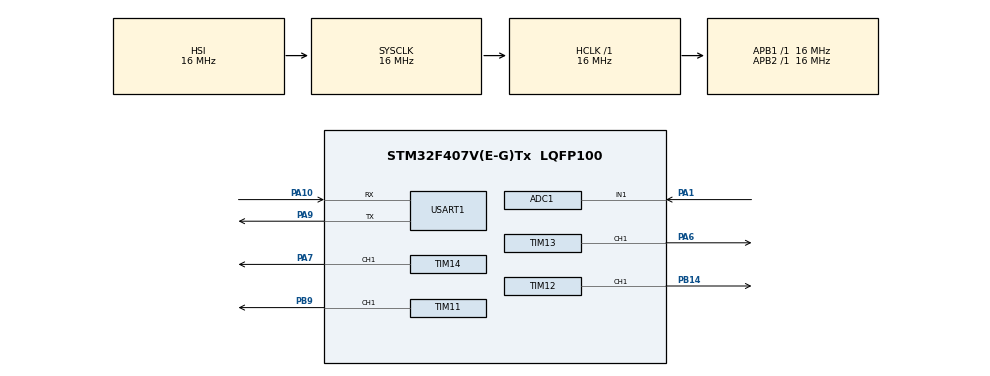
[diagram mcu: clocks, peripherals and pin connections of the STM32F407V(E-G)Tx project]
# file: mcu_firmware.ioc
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ADC1.Channel-1\#ChannelRegularConversion=ADC_CHANNEL_1
ADC1.ContinuousConvMode=ENABLE
ADC1.EOCSelection=ADC_EOC_SEQ_CONV
ADC1.NbrOfConversion=1
ADC1.NbrOfConversionFlag=1
ADC1.Rank-1\#ChannelRegularConversion=1
ADC1.SamplingTime-1\#ChannelRegularConversion=ADC_SAMPLETIME_3CYCLES
ADC1.master=1
Mcu.Family=STM32F4
Mcu.Name=STM32F407V(E-G)Tx
Mcu.Package=LQFP100
NVIC.PriorityGroup=NVIC_PRIORITYGROUP_4
NVIC.TIM1_TRG_COM_TIM11_IRQn=true\:0\:0\:false\:false\:true\:true\:true\:true
NVIC.TIM8_BRK_TIM12_IRQn=true\:0\:0\:false\:false\:true\:true\:true\:true
NVIC.TIM8_TRG_COM_TIM14_IRQn=true\:0\:0\:false\:false\:true\:true\:true\:true
NVIC.TIM8_UP_TIM13_IRQn=true\:0\:0\:false\:false\:true\:true\:true\:true
NVIC.USART1_IRQn=true\:0\:0\:false\:false\:true\:true\:true\:true
PA1.Signal=ADCx_IN1
PA10.Mode=Asynchronous
PA10.Signal=USART1_RX
PA6.GPIO_PuPd=GPIO_PULLDOWN
PA6.GPIO_Speed=GPIO_SPEED_FREQ_VERY_HIGH
PA6.Signal=S_TIM13_CH1
PA7.GPIO_PuPd=GPIO_PULLDOWN
PA7.GPIO_Speed=GPIO_SPEED_FREQ_VERY_HIGH
PA7.Signal=S_TIM14_CH1
PA9.Mode=Asynchronous
PA9.Signal=USART1_TX
PB14.GPIO_PuPd=GPIO_PULLDOWN
PB14.GPIO_Speed=GPIO_SPEED_FREQ_VERY_HIGH
PB14.Signal=S_TIM12_CH1
PB9.GPIO_PuPd=GPIO_PULLDOWN
PB9.GPIO_Speed=GPIO_SPEED_FREQ_VERY_HIGH
PB9.Signal=S_TIM11_CH1
PH0-OSC_IN.Mode=HSE-External-Oscillator
PH0-OSC_IN.Signal=RCC_OSC_IN
PH1-OSC_OUT.Mode=HSE-External-Oscillator
PH1-OSC_OUT.Signal=RCC_OSC_OUT
ProjectManager.HeapSize=0x200
ProjectManager.StackSize=0x400
ProjectManager.TargetToolchain=MDK-ARM V5.32
RCC.AHBFreq_Value=16000000
RCC.APB1Freq_Value=16000000
RCC.APB1TimFreq_Value=16000000
RCC.APB2Freq_Value=16000000
RCC.APB2TimFreq_Value=16000000
RCC.CortexFreq_Value=16000000
RCC.HCLKFreq_Value=16000000
RCC.HSE_VALUE=25000000
RCC.HSI_VALUE=16000000
RCC.LSE_VALUE=32768
RCC.SYSCLKFreq_VALUE=16000000
RCC.VCOOutputFreq_Value=192000000
SH.ADCx_IN1.0=ADC1_IN1,IN1
SH.S_TIM11_CH1.0=TIM11_CH1,PWM Generation1 CH1
SH.S_TIM12_CH1.0=TIM12_CH1,PWM Generation1 CH1
SH.S_TIM13_CH1.0=TIM13_CH1,PWM Generation1 CH1
SH.S_TIM14_CH1.0=TIM14_CH1,PWM Generation1 CH1
TIM11.Channel=TIM_CHANNEL_1
TIM11.Prescaler=15
TIM12.Channel-PWM\ Generation1\ CH1=TIM_CHANNEL_1
TIM12.Prescaler=15
TIM13.Channel=TIM_CHANNEL_1
TIM13.Prescaler=15
TIM14.Channel=TIM_CHANNEL_1
TIM14.Prescaler=15
USART1.VirtualMode=VM_ASYNC
VP_TIM11_VS_ClockSourceINT.Mode=Enable_Timer
VP_TIM12_VS_ClockSourceINT.Mode=Internal
VP_TIM13_VS_ClockSourceINT.Mode=Enable_Timer
VP_TIM14_VS_ClockSourceINT.Mode=Enable_Timer
board=custom

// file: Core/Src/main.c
/* USER CODE BEGIN Header */
/**
  ******************************************************************************
  * @file           : main.c
  * @brief          : Main program body
  ******************************************************************************
  * @attention
  *
  * Copyright (c) 2025 STMicroelectronics.
  * All rights reserved.
  *
  * This software is licensed under terms that can be found in the LICENSE file
  * in the root directory of this software component.
  * If no LICENSE file comes with this software, it is provided AS-IS.
  *
  ******************************************************************************
  */
/* USER CODE END Header */
#include "main.h"

/* USER CODE BEGIN Includes */
#include "func.h"
/* USER CODE END Includes */

ADC_HandleTypeDef hadc1;

TIM_HandleTypeDef htim11;
TIM_HandleTypeDef htim12;
TIM_HandleTypeDef htim13;
TIM_HandleTypeDef htim14;

UART_HandleTypeDef huart1;

void SystemClock_Config(void);
static void MX_GPIO_Init(void);
static void MX_TIM11_Init(void);
static void MX_TIM12_Init(void);
static void MX_TIM13_Init(void);
static void MX_TIM14_Init(void);
static void MX_USART1_UART_Init(void);
static void MX_ADC1_Init(void);

/* USER CODE BEGIN 0 */
uint16_t value;
/* USER CODE END 0 */

int main(void)
{

  /* MCU Configuration--------------------------------------------------------*/

  /* Reset of all peripherals, Initializes the Flash interface and the Systick. */
  HAL_Init();

  /* Configure the system clock */
  SystemClock_Config();

  /* Initialize all configured peripherals */
  MX_GPIO_Init();
  MX_TIM11_Init();
  MX_TIM12_Init();
  MX_TIM13_Init();
  MX_TIM14_Init();
  MX_USART1_UART_Init();
  MX_ADC1_Init();
  /* USER CODE BEGIN 2 */

	StartAxis(&htim11);

  /* USER CODE END 2 */

  /* Infinite loop */
  while (1)
  {
		HAL_ADC_Start(&hadc1);
		HAL_ADC_PollForConversion(&hadc1, 10);
		value = HAL_ADC_GetValue(&hadc1);
		HAL_ADC_Stop(&hadc1);
		if (value < 850)
		{
			value = 850;
		}
		SetPeriod(X_axis_htim, value/16);
		HAL_Delay(100);
  }
}

void SystemClock_Config(void)
{
  RCC_OscInitTypeDef RCC_OscInitStruct = {0};
  RCC_ClkInitTypeDef RCC_ClkInitStruct = {0};

  /** Configure the main internal regulator output voltage
  */
  __HAL_RCC_PWR_CLK_ENABLE();
  __HAL_PWR_VOLTAGESCALING_CONFIG(PWR_REGULATOR_VOLTAGE_SCALE1);

  /** Initializes the RCC Oscillators according to the specified parameters
  * in the RCC_OscInitTypeDef structure.
  */
  RCC_OscInitStruct.OscillatorType = RCC_OSCILLATORTYPE_HSI;
  RCC_OscInitStruct.HSIState = RCC_HSI_ON;
  RCC_OscInitStruct.HSICalibrationValue = RCC_HSICALIBRATION_DEFAULT;
  RCC_OscInitStruct.PLL.PLLState = RCC_PLL_NONE;
  if (HAL_RCC_OscConfig(&RCC_OscInitStruct) != HAL_OK)
  {
    Error_Handler();
  }

  /** Initializes the CPU, AHB and APB buses clocks
  */
  RCC_ClkInitStruct.ClockType = RCC_CLOCKTYPE_HCLK|RCC_CLOCKTYPE_SYSCLK
                              |RCC_CLOCKTYPE_PCLK1|RCC_CLOCKTYPE_PCLK2;
  RCC_ClkInitStruct.SYSCLKSource = RCC_SYSCLKSOURCE_HSI;
  RCC_ClkInitStruct.AHBCLKDivider = RCC_SYSCLK_DIV1;
  RCC_ClkInitStruct.APB1CLKDivider = RCC_HCLK_DIV1;
  RCC_ClkInitStruct.APB2CLKDivider = RCC_HCLK_DIV1;

  if (HAL_RCC_ClockConfig(&RCC_ClkInitStruct, FLASH_LATENCY_0) != HAL_OK)
  {
    Error_Handler();
  }
}

static void MX_ADC1_Init(void)
{

  ADC_ChannelConfTypeDef sConfig = {0};

  /** Configure the global features of the ADC (Clock, Resolution, Data Alignment and number of conversion)
  */
  hadc1.Instance = ADC1;
  hadc1.Init.ClockPrescaler = ADC_CLOCK_SYNC_PCLK_DIV2;
  hadc1.Init.Resolution = ADC_RESOLUTION_12B;
  hadc1.Init.ScanConvMode = DISABLE;
  hadc1.Init.ContinuousConvMode = ENABLE;
  hadc1.Init.DiscontinuousConvMode = DISABLE;
  hadc1.Init.ExternalTrigConvEdge = ADC_EXTERNALTRIGCONVEDGE_NONE;
  hadc1.Init.ExternalTrigConv = ADC_SOFTWARE_START;
  hadc1.Init.DataAlign = ADC_DATAALIGN_RIGHT;
  hadc1.Init.NbrOfConversion = 1;
  hadc1.Init.DMAContinuousRequests = DISABLE;
  hadc1.Init.EOCSelection = ADC_EOC_SEQ_CONV;
  if (HAL_ADC_Init(&hadc1) != HAL_OK)
  {
    Error_Handler();
  }

  /** Configure for the selected ADC regular channel its corresponding rank in the sequencer and its sample time.
  */
  sConfig.Channel = ADC_CHANNEL_1;
  sConfig.Rank = 1;
  sConfig.SamplingTime = ADC_SAMPLETIME_3CYCLES;
  if (HAL_ADC_ConfigChannel(&hadc1, &sConfig) != HAL_OK)
  {
    Error_Handler();
  }

}

static void MX_TIM11_Init(void)
{

  TIM_OC_InitTypeDef sConfigOC = {0};

  htim11.Instance = TIM11;
  htim11.Init.Prescaler = 15;
  htim11.Init.CounterMode = TIM_COUNTERMODE_UP;
  htim11.Init.Period = 65535;
  htim11.Init.ClockDivision = TIM_CLOCKDIVISION_DIV1;
  htim11.Init.AutoReloadPreload = TIM_AUTORELOAD_PRELOAD_DISABLE;
  if (HAL_TIM_Base_Init(&htim11) != HAL_OK)
  {
    Error_Handler();
  }
  if (HAL_TIM_PWM_Init(&htim11) != HAL_OK)
  {
    Error_Handler();
  }
  sConfigOC.OCMode = TIM_OCMODE_PWM1;
  sConfigOC.Pulse = 0;
  sConfigOC.OCPolarity = TIM_OCPOLARITY_HIGH;
  sConfigOC.OCFastMode = TIM_OCFAST_DISABLE;
  if (HAL_TIM_PWM_ConfigChannel(&htim11, &sConfigOC, TIM_CHANNEL_1) != HAL_OK)
  {
    Error_Handler();
  }
  HAL_TIM_MspPostInit(&htim11);

}

static void MX_TIM12_Init(void)
{

  TIM_ClockConfigTypeDef sClockSourceConfig = {0};
  TIM_OC_InitTypeDef sConfigOC = {0};

  htim12.Instance = TIM12;
  htim12.Init.Prescaler = 15;
  htim12.Init.CounterMode = TIM_COUNTERMODE_UP;
  htim12.Init.Period = 65535;
  htim12.Init.ClockDivision = TIM_CLOCKDIVISION_DIV1;
  htim12.Init.AutoReloadPreload = TIM_AUTORELOAD_PRELOAD_DISABLE;
  if (HAL_TIM_Base_Init(&htim12) != HAL_OK)
  {
    Error_Handler();
  }
  sClockSourceConfig.ClockSource = TIM_CLOCKSOURCE_INTERNAL;
  if (HAL_TIM_ConfigClockSource(&htim12, &sClockSourceConfig) != HAL_OK)
  {
    Error_Handler();
  }
  if (HAL_TIM_PWM_Init(&htim12) != HAL_OK)
  {
    Error_Handler();
  }
  sConfigOC.OCMode = TIM_OCMODE_PWM1;
  sConfigOC.Pulse = 0;
  sConfigOC.OCPolarity = TIM_OCPOLARITY_HIGH;
  sConfigOC.OCFastMode = TIM_OCFAST_DISABLE;
  if (HAL_TIM_PWM_ConfigChannel(&htim12, &sConfigOC, TIM_CHANNEL_1) != HAL_OK)
  {
    Error_Handler();
  }
  HAL_TIM_MspPostInit(&htim12);

}

static void MX_TIM13_Init(void)
{

  TIM_OC_InitTypeDef sConfigOC = {0};

  htim13.Instance = TIM13;
  htim13.Init.Prescaler = 15;
  htim13.Init.CounterMode = TIM_COUNTERMODE_UP;
  htim13.Init.Period = 65535;
  htim13.Init.ClockDivision = TIM_CLOCKDIVISION_DIV1;
  htim13.Init.AutoReloadPreload = TIM_AUTORELOAD_PRELOAD_DISABLE;
  if (HAL_TIM_Base_Init(&htim13) != HAL_OK)
  {
    Error_Handler();
  }
  if (HAL_TIM_PWM_Init(&htim13) != HAL_OK)
  {
    Error_Handler();
  }
  sConfigOC.OCMode = TIM_OCMODE_PWM1;
  sConfigOC.Pulse = 0;
  sConfigOC.OCPolarity = TIM_OCPOLARITY_HIGH;
  sConfigOC.OCFastMode = TIM_OCFAST_DISABLE;
  if (HAL_TIM_PWM_ConfigChannel(&htim13, &sConfigOC, TIM_CHANNEL_1) != HAL_OK)
  {
    Error_Handler();
  }
  HAL_TIM_MspPostInit(&htim13);

}

static void MX_TIM14_Init(void)
{

  TIM_OC_InitTypeDef sConfigOC = {0};

  htim14.Instance = TIM14;
  htim14.Init.Prescaler = 15;
  htim14.Init.CounterMode = TIM_COUNTERMODE_UP;
  htim14.Init.Period = 65535;
  htim14.Init.ClockDivision = TIM_CLOCKDIVISION_DIV1;
  htim14.Init.AutoReloadPreload = TIM_AUTORELOAD_PRELOAD_DISABLE;
  if (HAL_TIM_Base_Init(&htim14) != HAL_OK)
  {
    Error_Handler();
  }
  if (HAL_TIM_PWM_Init(&htim14) != HAL_OK)
  {
    Error_Handler();
  }
  sConfigOC.OCMode = TIM_OCMODE_PWM1;
  sConfigOC.Pulse = 0;
  sConfigOC.OCPolarity = TIM_OCPOLARITY_HIGH;
  sConfigOC.OCFastMode = TIM_OCFAST_DISABLE;
  if (HAL_TIM_PWM_ConfigChannel(&htim14, &sConfigOC, TIM_CHANNEL_1) != HAL_OK)
  {
    Error_Handler();
  }
  HAL_TIM_MspPostInit(&htim14);

}

static void MX_USART1_UART_Init(void)
{

  huart1.Instance = USART1;
  huart1.Init.BaudRate = 115200;
  huart1.Init.WordLength = UART_WORDLENGTH_8B;
  huart1.Init.StopBits = UART_STOPBITS_1;
  huart1.Init.Parity = UART_PARITY_NONE;
  huart1.Init.Mode = UART_MODE_TX_RX;
  huart1.Init.HwFlowCtl = UART_HWCONTROL_NONE;
  huart1.Init.OverSampling = UART_OVERSAMPLING_16;
  if (HAL_UART_Init(&huart1) != HAL_OK)
  {
    Error_Handler();
  }

}

static void MX_GPIO_Init(void)
{

  /* GPIO Ports Clock Enable */
  __HAL_RCC_GPIOH_CLK_ENABLE();
  __HAL_RCC_GPIOA_CLK_ENABLE();
  __HAL_RCC_GPIOB_CLK_ENABLE();

}

void Error_Handler(void)
{
  __disable_irq();
  while (1)
  {
  }
}
